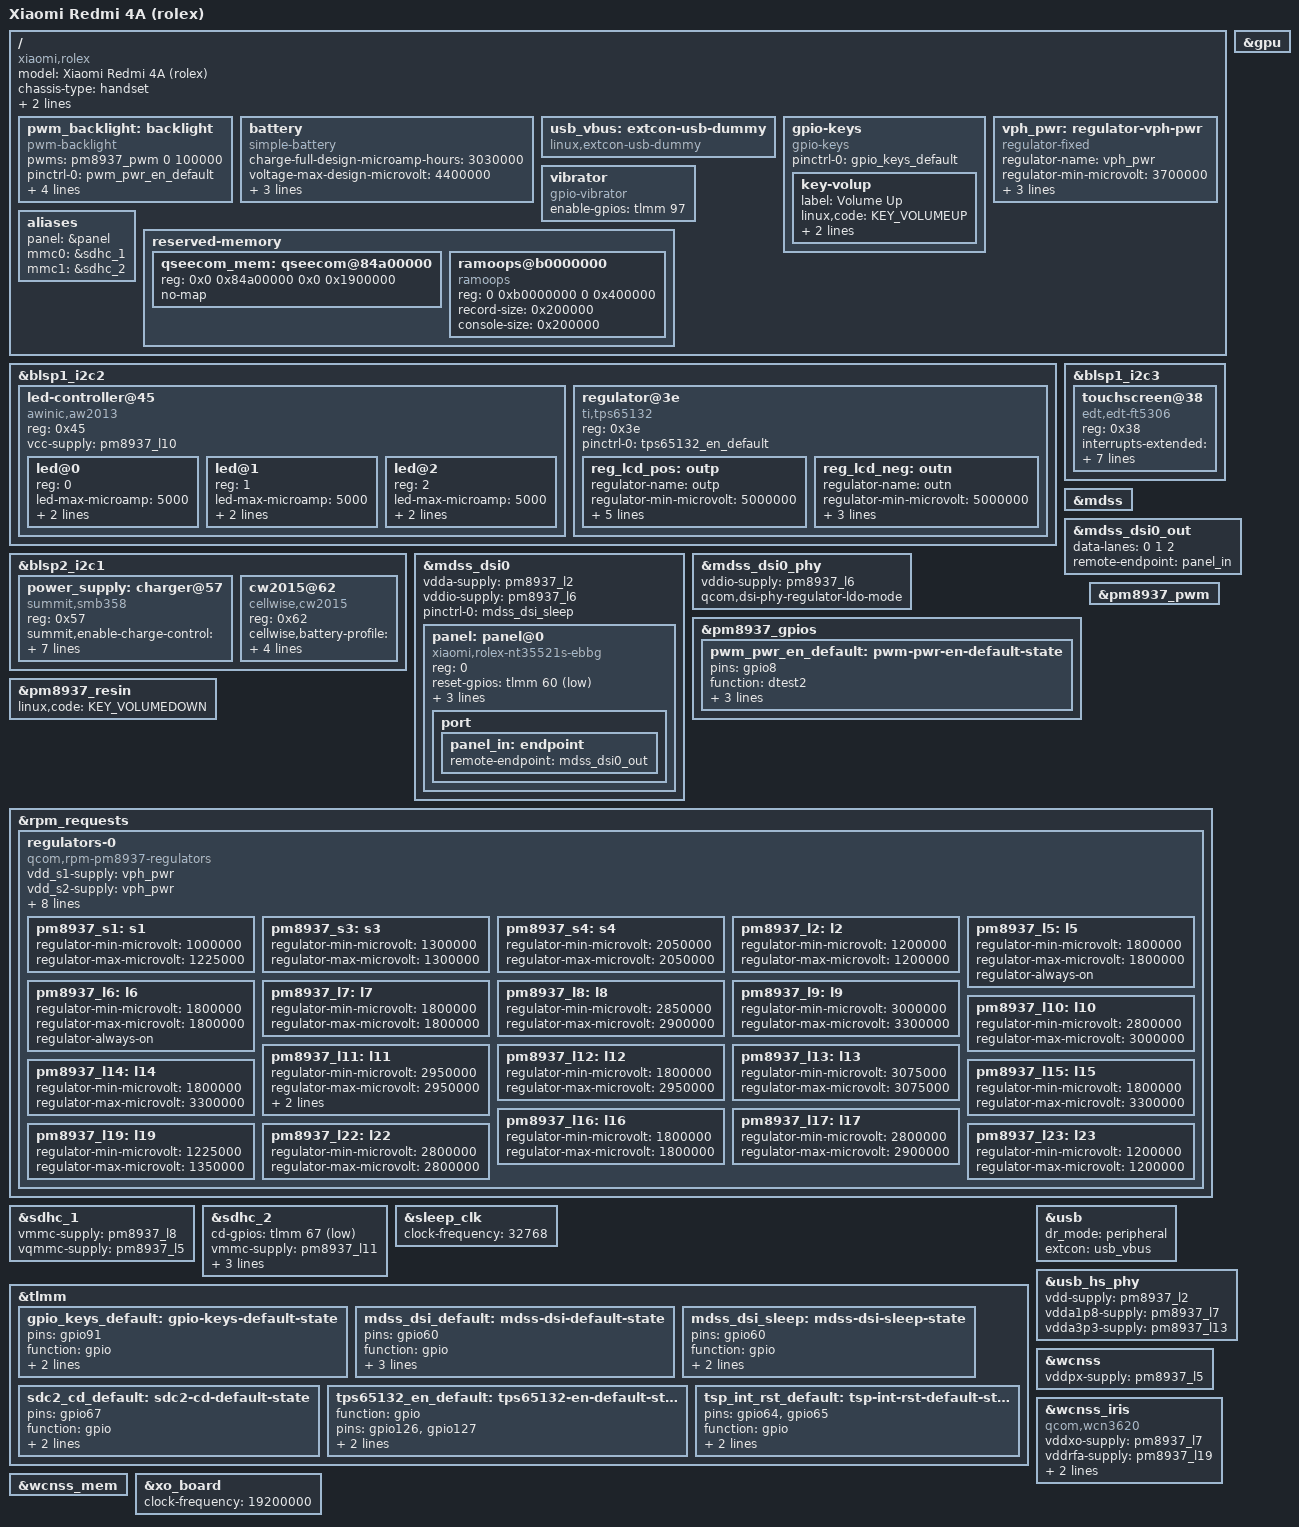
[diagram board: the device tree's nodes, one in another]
// SPDX-License-Identifier: GPL-2.0-only
/*
 * Copyright (c) 2025, Daniil Titov
 */

/dts-v1/;

#include <dt-bindings/power/summit,smb347-charger.h>
#include <dt-bindings/arm/qcom,ids.h>
#include <dt-bindings/gpio/gpio.h>
#include <dt-bindings/input/linux-event-codes.h>
#include <dt-bindings/leds/common.h>
#include "msm8917.dtsi"
#include "pm8937.dtsi"

/delete-node/ &qseecom_mem;

/ {
	model = "Xiaomi Redmi 4A (rolex)";
	compatible = "xiaomi,rolex", "qcom,msm8917";
	chassis-type = "handset";

	qcom,board-id= <0x1000b 1>, <0x2000b 1>;
	qcom,pmic-id = <0x10019 0x0 0x0 0x0>;

	pwm_backlight: backlight {
		compatible = "pwm-backlight";
		pwms = <&pm8937_pwm 0 100000>;

		pinctrl-0 = <&pwm_pwr_en_default>;
		pinctrl-names = "default";

		brightness-levels = <0 255>;
		num-interpolated-steps = <255>;
		default-brightness-level = <128>;

		enable-gpios = <&pm8937_gpios 8 GPIO_ACTIVE_LOW>;
	};

	battery: battery {
		compatible = "simple-battery";
		charge-full-design-microamp-hours = <3030000>;
		voltage-max-design-microvolt = <4400000>;
		voltage-min-design-microvolt = <3400000>;
		constant-charge-current-max-microamp = <1800000>;
		operating-range-celsius = <0 45>;
	};

	usb_vbus: extcon-usb-dummy {
		compatible = "linux,extcon-usb-dummy";
	};

	gpio-keys {
		compatible = "gpio-keys";

		pinctrl-0 = <&gpio_keys_default>;
		pinctrl-names = "default";

		key-volup {
			label = "Volume Up";
			linux,code = <KEY_VOLUMEUP>;
			gpios = <&tlmm 91 GPIO_ACTIVE_LOW>;
			debounce-interval = <15>;
		};
	};

	vph_pwr: regulator-vph-pwr {
		compatible = "regulator-fixed";
		regulator-name = "vph_pwr";
		regulator-min-microvolt = <3700000>;
		regulator-max-microvolt = <3700000>;
		regulator-always-on;
		regulator-boot-on;
	};

	vibrator {
		compatible = "gpio-vibrator";
		enable-gpios = <&tlmm 97 GPIO_ACTIVE_HIGH>;
	};

	aliases {
		panel = &panel;
		mmc0 = &sdhc_1; /* eMMC */
		mmc1 = &sdhc_2; /* SD card */
	};

	reserved-memory {
		qseecom_mem: qseecom@84a00000 {
			reg = <0x0 0x84a00000 0x0 0x1900000>;
			no-map;
		};

		ramoops@b0000000 {
			compatible = "ramoops";
			reg = <0 0xb0000000 0 0x400000>;
			record-size = <0x200000>;
			console-size = <0x200000>;
		};
	};
};

&blsp1_i2c2 {
	status = "okay";
	led-controller@45 {
		#address-cells = <1>;
		#size-cells = <0>;

		compatible = "awinic,aw2013";

		reg = <0x45>;

		vcc-supply = <&pm8937_l10>;

		led@0 {
			reg = <0>;
			led-max-microamp = <5000>;
			function = LED_FUNCTION_INDICATOR;
			color = <LED_COLOR_ID_RED>;
		};
		led@1 {
			reg = <1>;
			led-max-microamp = <5000>;
			function = LED_FUNCTION_INDICATOR;
			color = <LED_COLOR_ID_GREEN>;
		};
		led@2 {
			reg = <2>;
			led-max-microamp = <5000>;
			function = LED_FUNCTION_INDICATOR;
			color = <LED_COLOR_ID_BLUE>;
		};
	};

	regulator@3e {
		compatible = "ti,tps65132";
		reg = <0x3e>;

		pinctrl-names = "default";
		pinctrl-0 = <&tps65132_en_default>;

		reg_lcd_pos: outp {
			regulator-name = "outp";
			regulator-min-microvolt = <5000000>;
			regulator-max-microvolt = <5000000>;
			regulator-boot-on;
			regulator-always-on;
			enable-gpios = <&tlmm 126 GPIO_ACTIVE_HIGH>;
			regulator-active-discharge = <1>;
		};

		reg_lcd_neg: outn {
			regulator-name = "outn";
			regulator-min-microvolt = <5000000>;
			regulator-max-microvolt = <5000000>;
			enable-gpios = <&tlmm 127 GPIO_ACTIVE_HIGH>;
			regulator-active-discharge = <1>;
		};
	};
};

&blsp1_i2c3 {
	status = "okay";
	touchscreen@38 {
		compatible = "edt,edt-ft5306";
		reg = <0x38>;
		interrupts-extended = <&tlmm 65 IRQ_TYPE_LEVEL_LOW>;
		reset-gpios = <&tlmm 64 GPIO_ACTIVE_LOW>;
		pinctrl-0 = <&tsp_int_rst_default>;
		pinctrl-names = "default";
		vcc-supply = <&pm8937_l10>;
		iovcc-supply = <&pm8937_l5>;
		touchscreen-size-x = <720>;
		touchscreen-size-y = <1280>;
	};
};

&blsp2_i2c1 {
	status = "okay";
	power_supply: charger@57 {
		compatible = "summit,smb358";
		reg = <0x57>;

		summit,enable-charge-control = <SMB3XX_CHG_ENABLE_PIN_ACTIVE_HIGH>;
		summit,soft-compensation-method = <SMB3XX_SOFT_TEMP_COMPENSATE_CURRENT>;
		summit,chip-temperature-threshold-celsius = <100>;
		summit,enable-usb-charging;
		summit,enable-apsd;

		monitored-battery = <&battery>;
	};

	cw2015@62 {
		compatible = "cellwise,cw2015";
		reg = <0x62>;
		cellwise,battery-profile = /bits/ 8 <
			0x18 0x03 0x6A 0x6B 0x6D 0x6A 0x68 0x65
			0x60 0x63 0x60 0x54 0x5D 0x59 0x48 0x40
			0x38 0x31 0x27 0x24 0x28 0x31 0x43 0x4D
			0x28 0x49 0x0B 0x85 0x1C 0x37 0x57 0x6E
			0x79 0x7A 0x7A 0x7A 0x3D 0x1A 0x62 0x3F
			0x0A 0x44 0x34 0x55 0x82 0x97 0x9B 0x13
			0x41 0x81 0x94 0xC2 0x74 0x9C 0xBC 0xCB
			0x2F 0x7D 0x72 0xA5 0xB5 0xC1 0x95 0x61
		>;
		cellwise,monitor-interval-ms = <1000>;
		monitored-battery = <&battery>;
		power-supplies = <&power_supply>;
	};
};

&gpu {
	status = "okay";
};

&mdss {
	status = "okay";
};

&mdss_dsi0 {
	vdda-supply = <&pm8937_l2>;
	vddio-supply = <&pm8937_l6>;

	pinctrl-0 = <&mdss_dsi_default>;
	pinctrl-0 = <&mdss_dsi_sleep>;
	pinctrl-names = "default", "sleep";

	panel: panel@0 {
		compatible = "xiaomi,rolex-nt35521s-ebbg";
		reg = <0>;
		
		reset-gpios = <&tlmm 60 GPIO_ACTIVE_LOW>;

		vsn-supply = <&reg_lcd_neg>;
		vsp-supply = <&reg_lcd_pos>;

		backlight = <&pwm_backlight>;

		port {
			panel_in: endpoint {
				remote-endpoint = <&mdss_dsi0_out>;
			};
		};
	};
};

&mdss_dsi0_out {
	data-lanes = <0 1 2>;
	remote-endpoint = <&panel_in>;
};

&mdss_dsi0_phy {
	vddio-supply = <&pm8937_l6>;
	qcom,dsi-phy-regulator-ldo-mode;
};

&pm8937_gpios {
	pwm_pwr_en_default: pwm-pwr-en-default-state {
		pins = "gpio8";
		function = "dtest2";
		output-low;
		bias-disable;
		qcom,drive-strength = <2>;
	};
};

&pm8937_pwm {
	status = "okay";
};

&pm8937_resin {
	linux,code = <KEY_VOLUMEDOWN>;

	status = "okay";
};

&rpm_requests {
	regulators-0 {
		compatible = "qcom,rpm-pm8937-regulators";

		vdd_s1-supply = <&vph_pwr>;
		vdd_s2-supply = <&vph_pwr>;
		vdd_s3-supply = <&vph_pwr>;
		vdd_s4-supply = <&vph_pwr>;

		vdd_l1_l19-supply = <&pm8937_s3>;
		vdd_l2_l23-supply = <&pm8937_s3>;
		vdd_l3-supply = <&pm8937_s3>;
		vdd_l4_l5_l6_l7_l16-supply = <&pm8937_s4>;
		vdd_l8_l11_l12_l17_l22-supply = <&vph_pwr>;
		vdd_l9_l10_l13_l14_l15_l18-supply = <&vph_pwr>;

		pm8937_s1: s1 {
			regulator-min-microvolt = <1000000>;
			regulator-max-microvolt = <1225000>;
		};

		pm8937_s3: s3 {
			regulator-min-microvolt = <1300000>;
			regulator-max-microvolt = <1300000>;
		};

		pm8937_s4: s4 {
			regulator-min-microvolt = <2050000>;
			regulator-max-microvolt = <2050000>;
		};

		pm8937_l2: l2 {
			regulator-min-microvolt = <1200000>;
			regulator-max-microvolt = <1200000>;
		};

		pm8937_l5: l5 {
			regulator-min-microvolt = <1800000>;
			regulator-max-microvolt = <1800000>;
			regulator-always-on;
		};

		pm8937_l6: l6 {
			regulator-min-microvolt = <1800000>;
			regulator-max-microvolt = <1800000>;
			regulator-always-on;
		};

		pm8937_l7: l7 {
			regulator-min-microvolt = <1800000>;
			regulator-max-microvolt = <1800000>;
		};

		pm8937_l8: l8 {
			regulator-min-microvolt = <2850000>;
			regulator-max-microvolt = <2900000>;
		};

		pm8937_l9: l9 {
			regulator-min-microvolt = <3000000>;
			regulator-max-microvolt = <3300000>;
		};

		pm8937_l10: l10 {
			regulator-min-microvolt = <2800000>;
			regulator-max-microvolt = <3000000>;
		};

		pm8937_l11: l11 {
			regulator-min-microvolt = <2950000>;
			regulator-max-microvolt = <2950000>;
			regulator-allow-set-load;
			regulator-system-load = <200000>;
		};

		pm8937_l12: l12 {
			regulator-min-microvolt = <1800000>;
			regulator-max-microvolt = <2950000>;
		};

		pm8937_l13: l13 {
			regulator-min-microvolt = <3075000>;
			regulator-max-microvolt = <3075000>;
		};

		pm8937_l14: l14 {
			regulator-min-microvolt = <1800000>;
			regulator-max-microvolt = <3300000>;
		};

		pm8937_l15: l15 {
			regulator-min-microvolt = <1800000>;
			regulator-max-microvolt = <3300000>;
		};

		pm8937_l16: l16 {
			regulator-min-microvolt = <1800000>;
			regulator-max-microvolt = <1800000>;
		};

		pm8937_l17: l17 {
			regulator-min-microvolt = <2800000>;
			regulator-max-microvolt = <2900000>;
		};

		pm8937_l19: l19 {
			regulator-min-microvolt = <1225000>;
			regulator-max-microvolt = <1350000>;
		};

		pm8937_l22: l22 {
			regulator-min-microvolt = <2800000>;
			regulator-max-microvolt = <2800000>;
		};

		pm8937_l23: l23 {
			regulator-min-microvolt = <1200000>;
			regulator-max-microvolt = <1200000>;
		};
	};
};

&sdhc_1 {
	vmmc-supply = <&pm8937_l8>;
	vqmmc-supply = <&pm8937_l5>;

	status = "okay";
};

&sdhc_2 {
	cd-gpios = <&tlmm 67 GPIO_ACTIVE_LOW>;
	vmmc-supply = <&pm8937_l11>;
	vqmmc-supply = <&pm8937_l12>;
	pinctrl-0 = <&sdc2_default &sdc2_cd_default>;
	pinctrl-1 = <&sdc2_sleep &sdc2_cd_default>;
	pinctrl-names = "default", "sleep";

	status = "okay";
};

&sleep_clk {
	clock-frequency = <32768>;
};

&tlmm {
	gpio_keys_default: gpio-keys-default-state {
		pins = "gpio91";
		function = "gpio";
		drive-strength = <2>;
		bias-pull-up;
	};

	mdss_dsi_default: mdss-dsi-default-state {
		pins = "gpio60";
		function = "gpio";
		drive-strength = <8>;
		bias-disable;
		output-high;
	};

	mdss_dsi_sleep: mdss-dsi-sleep-state {
		pins = "gpio60";
		function = "gpio";
		drive-strength = <2>;
		bias-pull-down;
	};

	sdc2_cd_default: sdc2-cd-default-state {
		pins = "gpio67";
		function = "gpio";
		drive-strength = <2>;
		bias-disable;
	};

	tps65132_en_default: tps65132-en-default-state {
		function = "gpio";
		pins = "gpio126", "gpio127";
		drive-strength = <2>;
		bias-pull-down;
	};

	tsp_int_rst_default: tsp-int-rst-default-state {
		pins = "gpio64", "gpio65";
		function = "gpio";
		drive-strength = <8>;
		bias-pull-up;
	};
};

&usb {
	dr_mode = "peripheral";
	extcon = <&usb_vbus>;
	status = "okay";
};

&usb_hs_phy {
	/*
	 * Driver is not able to set init-seq
	 * qcom,init-seq = /bits/ 8 <0x0 0x53>,
	 *                          <0x1 0x39>,
	 *                          <0x2 0x37>;
	 */
	vdd-supply = <&pm8937_l2>;
	vdda1p8-supply = <&pm8937_l7>;
	vdda3p3-supply = <&pm8937_l13>;
	status = "okay";
};

&wcnss {
	vddpx-supply = <&pm8937_l5>;

	status = "okay";
};

&wcnss_iris {
	compatible = "qcom,wcn3620";
	vddxo-supply = <&pm8937_l7>;
	vddrfa-supply = <&pm8937_l19>;
	vddpa-supply = <&pm8937_l9>;
	vdddig-supply = <&pm8937_l5>;
};

&wcnss_mem {
	status = "okay";
};

&xo_board {
	clock-frequency = <19200000>;
};
